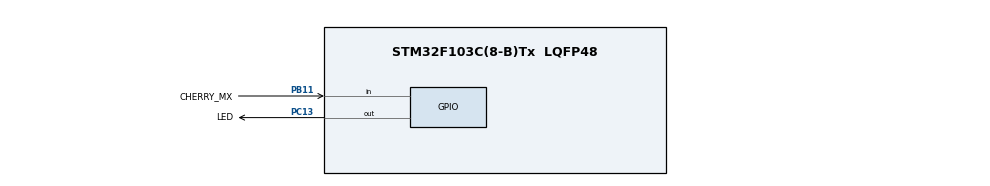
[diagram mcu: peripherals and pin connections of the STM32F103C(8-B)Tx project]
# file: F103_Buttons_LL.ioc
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Mcu.Family=STM32F1
Mcu.Name=STM32F103C(8-B)Tx
Mcu.Package=LQFP48
NVIC.PriorityGroup=NVIC_PRIORITYGROUP_4
PA13.Mode=Serial_Wire
PA13.Signal=SYS_JTMS-SWDIO
PA14.Mode=Serial_Wire
PA14.Signal=SYS_JTCK-SWCLK
PB11.GPIO_Label=CHERRY_MX
PB11.GPIO_PuPd=GPIO_PULLUP
PB11.Signal=GPIO_Input
PC13-TAMPER-RTC.GPIO_Label=LED
PC13-TAMPER-RTC.GPIO_PuPd=GPIO_PULLUP
PC13-TAMPER-RTC.Signal=GPIO_Output
PC14-OSC32_IN.Mode=LSE-External-Oscillator
PC14-OSC32_IN.Signal=RCC_OSC32_IN
PC15-OSC32_OUT.Mode=LSE-External-Oscillator
PC15-OSC32_OUT.Signal=RCC_OSC32_OUT
PD0-OSC_IN.Mode=HSE-External-Oscillator
PD0-OSC_IN.Signal=RCC_OSC_IN
PD1-OSC_OUT.Mode=HSE-External-Oscillator
PD1-OSC_OUT.Signal=RCC_OSC_OUT
ProjectManager.HeapSize=0x200
ProjectManager.StackSize=0x400
ProjectManager.TargetToolchain=STM32CubeIDE
RCC.AHBFreq_Value=72000000
RCC.APB1CLKDivider=RCC_HCLK_DIV2
RCC.APB1Freq_Value=36000000
RCC.APB1TimFreq_Value=72000000
RCC.APB2Freq_Value=72000000
RCC.APB2TimFreq_Value=72000000
RCC.EnbaleCSS=true
RCC.HCLKFreq_Value=72000000
RCC.PLLMUL=RCC_PLL_MUL9
RCC.PLLSourceVirtual=RCC_PLLSOURCE_HSE
RCC.SYSCLKFreq_VALUE=72000000
RCC.SYSCLKSource=RCC_SYSCLKSOURCE_PLLCLK
RCC.USBFreq_Value=48000000
RCC.USBPrescaler=RCC_USBCLKSOURCE_PLL_DIV1_5
board=custom

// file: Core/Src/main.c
/* USER CODE BEGIN Header */
/**
  ******************************************************************************
  * @file           : main.c
  * @brief          : Main program body
  ******************************************************************************
  * @attention
  *
  * Copyright (c) 2024 STMicroelectronics.
  * All rights reserved.
  *
  * This software is licensed under terms that can be found in the LICENSE file
  * in the root directory of this software component.
  * If no LICENSE file comes with this software, it is provided AS-IS.
  *
  ******************************************************************************
  */
/* USER CODE END Header */
#include "main.h"
#include "gpio.h"

/* USER CODE BEGIN Includes */
#include "btnFcn.h"
/* USER CODE END Includes */

/* USER CODE BEGIN PV */
static uint8_t cherryMx = 0;
static uint8_t debug = 0;
/* USER CODE END PV */

void SystemClock_Config(void);
/* USER CODE BEGIN PFP */
static void ToggleLed(void);
/* USER CODE END PFP */

int main(void)
{

  /* MCU Configuration--------------------------------------------------------*/

  /* Reset of all peripherals, Initializes the Flash interface and the Systick. */
  LL_APB2_GRP1_EnableClock(LL_APB2_GRP1_PERIPH_AFIO);
  LL_APB1_GRP1_EnableClock(LL_APB1_GRP1_PERIPH_PWR);

  /* System interrupt init*/
  NVIC_SetPriorityGrouping(NVIC_PRIORITYGROUP_4);

  /* SysTick_IRQn interrupt configuration */
  NVIC_SetPriority(SysTick_IRQn, NVIC_EncodePriority(NVIC_GetPriorityGrouping(),15, 0));

  /** NOJTAG: JTAG-DP Disabled and SW-DP Enabled
  */
  LL_GPIO_AF_Remap_SWJ_NOJTAG();

  /* Configure the system clock */
  SystemClock_Config();

  /* Initialize all configured peripherals */
  MX_GPIO_Init();

  /* Infinite loop */
  /* USER CODE BEGIN WHILE */
  while (1)
  {
    debug = BtnRelease(&cherryMx, CHERRY_MX_GPIO_Port, CHERRY_MX_Pin, ToggleLed);
    //debug = BtnPress(&cherryMx, CHERRY_MX_GPIO_Port, CHERRY_MX_Pin, ToggleLed);
    /* USER CODE END WHILE */

  }
}

void SystemClock_Config(void)
{
  LL_FLASH_SetLatency(LL_FLASH_LATENCY_2);
  while(LL_FLASH_GetLatency()!= LL_FLASH_LATENCY_2)
  {
  }
  LL_RCC_HSE_Enable();

   /* Wait till HSE is ready */
  while(LL_RCC_HSE_IsReady() != 1)
  {

  }
  LL_RCC_HSE_EnableCSS();
  LL_RCC_PLL_ConfigDomain_SYS(LL_RCC_PLLSOURCE_HSE_DIV_1, LL_RCC_PLL_MUL_9);
  LL_RCC_PLL_Enable();

   /* Wait till PLL is ready */
  while(LL_RCC_PLL_IsReady() != 1)
  {

  }
  LL_RCC_SetAHBPrescaler(LL_RCC_SYSCLK_DIV_1);
  LL_RCC_SetAPB1Prescaler(LL_RCC_APB1_DIV_2);
  LL_RCC_SetAPB2Prescaler(LL_RCC_APB2_DIV_1);
  LL_RCC_SetSysClkSource(LL_RCC_SYS_CLKSOURCE_PLL);

   /* Wait till System clock is ready */
  while(LL_RCC_GetSysClkSource() != LL_RCC_SYS_CLKSOURCE_STATUS_PLL)
  {

  }
  LL_Init1msTick(72000000);
  LL_SetSystemCoreClock(72000000);
}

/* USER CODE BEGIN 4 */
void ToggleLed(void)
{
  LL_GPIO_TogglePin(LED_GPIO_Port, LED_Pin);
}
/* USER CODE END 4 */

void Error_Handler(void)
{
  __disable_irq();
  while (1)
  {
  }
}
